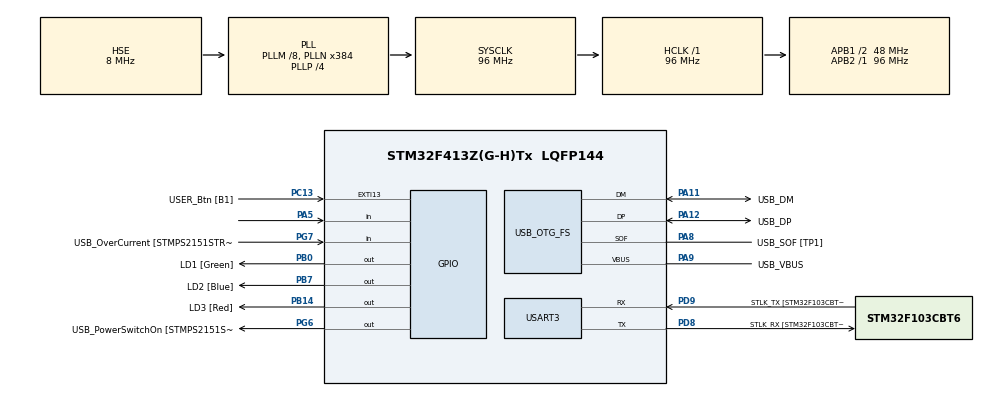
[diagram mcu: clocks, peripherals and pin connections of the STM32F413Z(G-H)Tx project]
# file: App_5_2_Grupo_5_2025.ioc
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Mcu.Family=STM32F4
Mcu.Name=STM32F413Z(G-H)Tx
Mcu.Package=LQFP144
NVIC.PriorityGroup=NVIC_PRIORITYGROUP_4
PA10.GPIO_Label=USB_ID
PA10.Signal=USB_OTG_FS_ID
PA11.GPIO_Label=USB_DM
PA11.Mode=Device_Only
PA11.Signal=USB_OTG_FS_DM
PA12.GPIO_Label=USB_DP
PA12.Mode=Device_Only
PA12.Signal=USB_OTG_FS_DP
PA13.GPIO_Label=TMS
PA13.Mode=Serial_Wire
PA13.Signal=SYS_JTMS-SWDIO
PA14.GPIO_Label=TCK
PA14.Mode=Serial_Wire
PA14.Signal=SYS_JTCK-SWCLK
PA5.Signal=GPIO_Input
PA8.GPIO_Label=USB_SOF [TP1]
PA8.Mode=Activate_SOF_FS
PA8.Signal=USB_OTG_FS_SOF
PA9.GPIO_Label=USB_VBUS
PA9.Mode=Activate_VBUS
PA9.Signal=USB_OTG_FS_VBUS
PB0.GPIO_Label=LD1 [Green]
PB0.Signal=GPIO_Output
PB14.GPIO_Label=LD3 [Red]
PB14.Signal=GPIO_Output
PB3.GPIO_Label=SWO
PB3.Signal=SYS_JTDO-SWO
PB7.GPIO_Label=LD2 [Blue]
PB7.Signal=GPIO_Output
PC13.GPIO_Label=USER_Btn [B1]
PC13.Signal=GPXTI13
PC14-OSC32_IN.Mode=LSE-External-Oscillator
PC14-OSC32_IN.Signal=RCC_OSC32_IN
PC15-OSC32_OUT.Mode=LSE-External-Oscillator
PC15-OSC32_OUT.Signal=RCC_OSC32_OUT
PD8.GPIO_Label=STLK_RX [STM32F103CBT6_PA3]
PD8.Mode=Asynchronous
PD8.Signal=USART3_TX
PD9.GPIO_Label=STLK_TX [STM32F103CBT6_PA2]
PD9.Mode=Asynchronous
PD9.Signal=USART3_RX
PG6.GPIO_Label=USB_PowerSwitchOn [STMPS2151STR_EN]
PG6.Signal=GPIO_Output
PG7.GPIO_Label=USB_OverCurrent [STMPS2151STR_FAULT]
PG7.Signal=GPIO_Input
PH0\ -\ OSC_IN.GPIO_Label=MCO
PH0\ -\ OSC_IN.Mode=HSE-External-Clock-Source
PH0\ -\ OSC_IN.Signal=RCC_OSC_IN
PH1\ -\ OSC_OUT.Mode=HSE-External-Clock-Source
PH1\ -\ OSC_OUT.Signal=RCC_OSC_OUT
ProjectManager.HeapSize=0x200
ProjectManager.StackSize=0x400
ProjectManager.TargetToolchain=STM32CubeIDE
RCC.48MHZClocksFreq_Value=24000000
RCC.AHBFreq_Value=96000000
RCC.APB1CLKDivider=RCC_HCLK_DIV2
RCC.APB1Freq_Value=48000000
RCC.APB1TimFreq_Value=96000000
RCC.APB2Freq_Value=96000000
RCC.APB2TimFreq_Value=96000000
RCC.CortexFreq_Value=96000000
RCC.HCLKFreq_Value=96000000
RCC.HSE_VALUE=8000000
RCC.HSI_VALUE=16000000
RCC.PLLM=8
RCC.PLLMUL=RCC_PLL_MUL9
RCC.PLLN=384
RCC.PLLP=RCC_PLLP_DIV4
RCC.PLLQ=8
RCC.PRESCALERUSB=RCC_USBCLKSOURCE_PLL_DIV1_5
RCC.SYSCLKFreq_VALUE=96000000
RCC.SYSCLKSource=RCC_SYSCLKSOURCE_PLLCLK
RCC.SYSCLKSourceVirtual=RCC_SYSCLKSOURCE_PLLCLK
RCC.USBFreq_Value=48000000
RCC.VCOOutputFreq_Value=384000000
USART3.VirtualMode=VM_ASYNC
USB_OTG_FS.VirtualMode=Device_Only
board=NUCLEO-F413ZH

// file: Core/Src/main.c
/* USER CODE BEGIN Header */
/**
  ******************************************************************************
  * @file           : main.c
  * @brief          : Main program body
  ******************************************************************************
  * @attention
  *
  * Copyright (c) 2025 STMicroelectronics.
  * All rights reserved.
  *
  * This software is licensed under terms that can be found in the LICENSE file
  * in the root directory of this software component.
  * If no LICENSE file comes with this software, it is provided AS-IS.
  *
  ******************************************************************************
  */
/* USER CODE END Header */
/* INCLUDES */

#include "main.h"
#include "API_GPIO.h"  // Driver personalizado para manejo de LEDs y pulsador externo

// Definiciones de tiempo en milisegundos
/* DEFINICIONES DE TIEMPO Y ESTADOS */

#define LED_ON_TIME 200  // Duración del encendido de cada LED
#define LED_OFF_TIME 200  // Duración del apagado de cada LED

// Estados posibles del LED
typedef enum {
  LED_STATE_ON,
  LED_STATE_OFF
} led_state_t;

// VARIABLES DE CONTROL DE LA SECUENCIA
// Se comentan porque se definen dentro de main()
// static uint32_t lastTick = 0;
// static uint8_t currentLed = 0;

UART_HandleTypeDef huart3;             // UART3 (no utilizada en esta aplicación)
PCD_HandleTypeDef hpcd_USB_OTG_FS;     // USB OTG FS (no utilizado en esta aplicación)

void SystemClock_Config(void);             // Configura el reloj del sistema
// static void MX_GPIO_Init(void);         // Comentado porque se usa el del driver
static void MX_USART3_UART_Init(void);     // Inicializa UART3
static void MX_USB_OTG_FS_PCD_Init(void);  // Inicializa USB OTG FS

/**
  * @brief  Punto de entrada principal de la aplicación
  * @retval int
  */
int main(void)
{

  /* MCU Configuration--------------------------------------------------------*/

  HAL_Init();              // Inicializa HAL y el sistema de interrupciones

  SystemClock_Config();    // Configura el reloj del sistema

  // Inicializa periféricos configurados
  MX_GPIO_Init();          // Inicializa GPIOs (LEDs y pulsador externo)
  MX_USART3_UART_Init();   // UART (no usada en esta app)
  MX_USB_OTG_FS_PCD_Init();// USB (no usado en esta app)

  /* USER CODE BEGIN 2 */

  debounceInit_GPIO();     // Inicializa lógica anti-rebote del pulsador

  // Variables locales para controlar la secuencia de LEDs
  uint32_t lastTick = HAL_GetTick();  // Marca de tiempo inicial
  uint8_t currentLed = 0;             // LED actual encendido
  int8_t direction = 1;               // Dirección de la secuencia (1 o -1)
  led_state_t ledState = LED_STATE_ON;

  writeLedOn_GPIO(getLedByIndex(currentLed)); // Enciende el primer LED

  /* USER CODE END 2 */

  /* Infinite loop */
  while (1)
  {

    debounceUpdate_GPIO();  // Actualiza estado del pulsador con anti-rebote

    if (readKey_GPIO()) {
      direction *= -1;      // Invierte la dirección de la secuencia
    }

    uint32_t now = HAL_GetTick();  // Obtiene el tiempo actual

    // Lógica no bloqueante para alternar LEDs
    if (ledState == LED_STATE_ON && (now - lastTick >= LED_ON_TIME)) {
      writeLedOff_GPIO(getLedByIndex(currentLed)); // Apaga LED actual
      lastTick = now;
      ledState = LED_STATE_OFF;
    }
    else if (ledState == LED_STATE_OFF && (now - lastTick >= LED_OFF_TIME)) {
      currentLed = (currentLed + direction + getLedCount()) % getLedCount(); // Calcula siguiente LED
      writeLedOn_GPIO(getLedByIndex(currentLed)); // Enciende siguiente LED
      lastTick = now;
      ledState = LED_STATE_ON;
    }

  }
}

/**
  * @brief Configura el reloj del sistema
  * @retval None
  */
void SystemClock_Config(void)
{
  RCC_OscInitTypeDef RCC_OscInitStruct = {0};
  RCC_ClkInitTypeDef RCC_ClkInitStruct = {0};

  __HAL_RCC_PWR_CLK_ENABLE();
  __HAL_PWR_VOLTAGESCALING_CONFIG(PWR_REGULATOR_VOLTAGE_SCALE1);

  RCC_OscInitStruct.OscillatorType = RCC_OSCILLATORTYPE_HSE;
  RCC_OscInitStruct.HSEState = RCC_HSE_BYPASS;
  RCC_OscInitStruct.PLL.PLLState = RCC_PLL_ON;
  RCC_OscInitStruct.PLL.PLLSource = RCC_PLLSOURCE_HSE;
  RCC_OscInitStruct.PLL.PLLM = 8;
  RCC_OscInitStruct.PLL.PLLN = 384;
  RCC_OscInitStruct.PLL.PLLP = RCC_PLLP_DIV4;
  RCC_OscInitStruct.PLL.PLLQ = 8;
  RCC_OscInitStruct.PLL.PLLR = 2;
  if (HAL_RCC_OscConfig(&RCC_OscInitStruct) != HAL_OK)
  {
    Error_Handler();  // Entra en modo error si falla la configuración
  }

  RCC_ClkInitStruct.ClockType = RCC_CLOCKTYPE_HCLK|RCC_CLOCKTYPE_SYSCLK
                              |RCC_CLOCKTYPE_PCLK1|RCC_CLOCKTYPE_PCLK2;
  RCC_ClkInitStruct.SYSCLKSource = RCC_SYSCLKSOURCE_PLLCLK;
  RCC_ClkInitStruct.AHBCLKDivider = RCC_SYSCLK_DIV1;
  RCC_ClkInitStruct.APB1CLKDivider = RCC_HCLK_DIV2;
  RCC_ClkInitStruct.APB2CLKDivider = RCC_HCLK_DIV1;

  if (HAL_RCC_ClockConfig(&RCC_ClkInitStruct, FLASH_LATENCY_3) != HAL_OK)
  {
    Error_Handler();  // Entra en modo error si falla la configuración
  }
}

/**
  * @brief Inicializa UART3 (no utilizada en esta aplicación)
  * @param None
  * @retval None
  */
static void MX_USART3_UART_Init(void)
{
  huart3.Instance = USART3;
  huart3.Init.BaudRate = 115200;
  huart3.Init.WordLength = UART_WORDLENGTH_8B;
  huart3.Init.StopBits = UART_STOPBITS_1;
  huart3.Init.Parity = UART_PARITY_NONE;
  huart3.Init.Mode = UART_MODE_TX_RX;
  huart3.Init.HwFlowCtl = UART_HWCONTROL_NONE;
  huart3.Init.OverSampling = UART_OVERSAMPLING_16;
  if (HAL_UART_Init(&huart3) != HAL_OK)
  {
    Error_Handler();
  }
}

/**
  * @brief Inicializa USB OTG FS (no utilizado en esta aplicación)
  * @param None
  * @retval None
  */
static void MX_USB_OTG_FS_PCD_Init(void)
{
  hpcd_USB_OTG_FS.Instance = USB_OTG_FS;
  hpcd_USB_OTG_FS.Init.dev_endpoints = 6;
  hpcd_USB_OTG_FS.Init.speed = PCD_SPEED_FULL;
  hpcd_USB_OTG_FS.Init.dma_enable = DISABLE;
  hpcd_USB_OTG_FS.Init.phy_itface = PCD_PHY_EMBEDDED;
  hpcd_USB_OTG_FS.Init.Sof_enable = ENABLE;
  hpcd_USB_OTG_FS.Init.low_power_enable = DISABLE;
  hpcd_USB_OTG_FS.Init.lpm_enable = DISABLE;
  hpcd_USB_OTG_FS.Init.battery_charging_enable = ENABLE;
  hpcd_USB_OTG_FS.Init.vbus_sensing_enable = ENABLE;
  hpcd_USB_OTG_FS.Init.use_dedicated_ep1 = DISABLE;
  if (HAL_PCD_Init(&hpcd_USB_OTG_FS) != HAL_OK)
  {
    Error_Handler();
  }
}

/**
  * @brief GPIO Initialization Function
  * @param None
  * @retval*/
void Error_Handler(void)
{
  __disable_irq();
  while (1)
  {
  }
}
